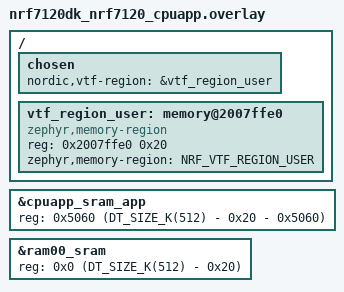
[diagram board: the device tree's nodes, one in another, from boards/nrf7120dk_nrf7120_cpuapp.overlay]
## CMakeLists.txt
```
#
# Copyright (c) 2026 Nordic Semiconductor ASA
#
# SPDX-License-Identifier: LicenseRef-Nordic-5-Clause
#

cmake_minimum_required(VERSION 3.20.0)

find_package(Zephyr REQUIRED HINTS $ENV{ZEPHYR_BASE})
project(vtf_monitoring_sample)

target_sources(app PRIVATE src/main.c)
target_sources_ifdef(CONFIG_SAMPLE_VTF_CUSTOM_BATTERY_VOLTAGE_MONITOR app PRIVATE src/mock_battery_provider.c)
```

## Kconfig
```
#
# Copyright (c) 2026 Nordic Semiconductor ASA
#
# SPDX-License-Identifier: LicenseRef-Nordic-5-Clause
#

config SAMPLE_VTF_CUSTOM_BATTERY_VOLTAGE_MONITOR
	bool "Enables customer battery voltage monitor"

menu "Zephyr"
source "Kconfig.zephyr"
endmenu
```

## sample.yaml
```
sample:
  description: Sample showing how to configure VTF monitoring subsystem
  name: VTF monitoring sample

common:
  sysbuild: true
  build_only: true
  integration_platforms:
    - nrf7120dk/nrf7120/cpuapp
  platform_allow:
    - nrf7120dk/nrf7120/cpuapp
  tags:
    - ci_build
    - sysbuild
    - ci_samples_vtf_monitoring

tests:
  sample.vtf_monitoring: {}
  sample.vtf_monitoring.battery_override:
    extra_configs:
      - CONFIG_VTF_BATTERY_VOLTAGE_MONITOR=n
      - CONFIG_SAMPLE_VTF_CUSTOM_BATTERY_VOLTAGE_MONITOR=y
  sample.vtf_monitoring.xo_offset_uicr_override:
    extra_dtc_overlay_files:
      - "xo_offset_uicr.overlay"
```

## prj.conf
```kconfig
#
# Copyright (c) 2026 Nordic Semiconductor ASA
#
# SPDX-License-Identifier: LicenseRef-Nordic-5-Clause
#

CONFIG_VTF_MONITORING=y
CONFIG_VTF_DIE_TEMP_MONITOR=y
CONFIG_VTF_BATTERY_VOLTAGE_MONITOR=y
CONFIG_VTF_FREQ_OFFSET_MONITOR=y
CONFIG_LOG=y
```

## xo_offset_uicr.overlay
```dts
/*
 * Copyright (c) 2026 Nordic Semiconductor ASA
 *
 * SPDX-License-Identifier: LicenseRef-Nordic-5-Clause
 */

&uicr {
	xtalcomp-offset = <42>;
};
```

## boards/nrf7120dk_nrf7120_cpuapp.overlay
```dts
/*
 * Copyright (c) 2026 Nordic Semiconductor ASA
 *
 * SPDX-License-Identifier: LicenseRef-Nordic-5-Clause
 */

/ {
	chosen {
		nordic,vtf-region = &vtf_region_user;
	};

	/* Last 32 bytes of RAM00 reserved for VTF region */
	vtf_region_user: memory@2007ffe0 {
		compatible = "zephyr,memory-region", "mmio-sram";
		reg = <0x2007ffe0 0x20>;
		zephyr,memory-region = "NRF_VTF_REGION_USER";
		status = "okay";
	};
};

&cpuapp_sram_app {
	reg = <0x5060 (DT_SIZE_K(512) - 0x20 - 0x5060)>;
};

&ram00_sram {
	reg = <0x0 (DT_SIZE_K(512) - 0x20)>;
	ranges = <0x0 0x0 (DT_SIZE_K(512) - 0x20)>;
};
```

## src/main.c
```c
/*
 * Copyright (c) 2026 Nordic Semiconductor ASA
 *
 * SPDX-License-Identifier: LicenseRef-Nordic-5-Clause
 */

/** @file
 * @brief VTF monitoring framework sample
 */

#include <stdlib.h>
#include <zephyr/kernel.h>
#include <zephyr/devicetree.h>
#include <zephyr/logging/log.h>
#include <drivers/vtf_monitoring/vtf_monitoring.h>

LOG_MODULE_REGISTER(vtf_monitoring_sample, CONFIG_LOG_DEFAULT_LEVEL);

#define SLEEP_TIME_MS 1000

#if DT_HAS_CHOSEN(nordic_vtf_region)
#define VTF_NODE DT_CHOSEN(nordic_vtf_region)
#else
#error " 'nordic,vtf-region' must be chosen and enabled"
#endif

int main(void)
{
	while (1) {
		int32_t temp = vtf_snapshots[VTF_CH_DIE_TEMP].i32;
		int32_t batt = vtf_snapshots[VTF_CH_BATTERY_VOLTAGE].i32;
		int32_t xo = vtf_snapshots[VTF_CH_FREQ_OFFSET].i32;

		LOG_INF("die temp: %d.%02d C", temp / 100, abs(temp % 100));
		LOG_INF("battery voltage: %d mV", batt);
		LOG_INF("XO offset: %d ppm", xo);

		k_msleep(SLEEP_TIME_MS);
	}
	return 0;
}
```

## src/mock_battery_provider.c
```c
/*
 * Copyright (c) 2026 Nordic Semiconductor ASA
 *
 * SPDX-License-Identifier: LicenseRef-Nordic-5-Clause
 */

/**
 * Tier-2 provider example: no sensor API, no devicetree binding, just
 * a plain init()/sample() pair registered with VTF_CHANNEL_DEFINE().
 * Stands in for whatever a customer's own fuel-gauge library or raw
 * register read would do; simulates a battery discharging from 4200
 * to 3300 mV and back, to make the changing value visible in the log.
 */

#include <zephyr/kernel.h>
#include <zephyr/device.h>
#include <zephyr/logging/log.h>

#include <vtf_monitoring/vtf_monitoring.h>

#define MOCK_BATTERY_MAX_MV  4200
#define MOCK_BATTERY_MIN_MV  3300
#define MOCK_BATTERY_STEP_MV 20

static int32_t mock_battery_mv = MOCK_BATTERY_MAX_MV;

#define MOCK_VTF_BATTERY_VOLTAGE_MONITOR_INTERVAL_MS 10000

LOG_MODULE_REGISTER(battery_voltage_monitor, LOG_LEVEL_INF);

static K_SEM_DEFINE(sensor_state_lock, 1, 1);

static struct vtf_sample sensor_state = {
	.type = VTF_SAMPLE_TYPE_INT,
	.value.i32 = 0,
	.timestamp_ms = 0,
	.status = VTF_STATUS_UNINITIALISED,
};

static void battery_voltage_work_handler(struct k_work *work);
static void reschedule_battery_voltage_work(void);

static K_WORK_DELAYABLE_DEFINE(battery_voltage_work, battery_voltage_work_handler);

static void reschedule_battery_voltage_work(void)
{
	k_work_schedule(&battery_voltage_work,
			K_MSEC(MOCK_VTF_BATTERY_VOLTAGE_MONITOR_INTERVAL_MS));
}

static void battery_voltage_work_handler(struct k_work *work)
{
	ARG_UNUSED(work);

	mock_battery_mv -= MOCK_BATTERY_STEP_MV;
	if (mock_battery_mv <= MOCK_BATTERY_MIN_MV) {
		mock_battery_mv = MOCK_BATTERY_MAX_MV;
	}

	k_sem_take(&sensor_state_lock, K_FOREVER);
	sensor_state.value.i32 = mock_battery_mv;
	sensor_state.timestamp_ms = k_uptime_get();
	sensor_state.status = VTF_STATUS_OK;
	k_sem_give(&sensor_state_lock);

	reschedule_battery_voltage_work();
}

static int mock_battery_init(void)
{
	k_work_schedule(&battery_voltage_work, K_NO_WAIT);
	return 0;
}

static int mock_battery_sample(struct vtf_sample *out)
{
	if (out == NULL) {
		return -EINVAL;
	}

	k_sem_take(&sensor_state_lock, K_FOREVER);
	*out = sensor_state;
	k_sem_give(&sensor_state_lock);
	return 0;
}

VTF_CHANNEL_DEFINE(vtf_channel_battery_voltage, VTF_CH_BATTERY_VOLTAGE, mock_battery_sample,
		   mock_battery_init, VTF_SAMPLE_TYPE_INT, i32, MOCK_BATTERY_MAX_MV);
```
